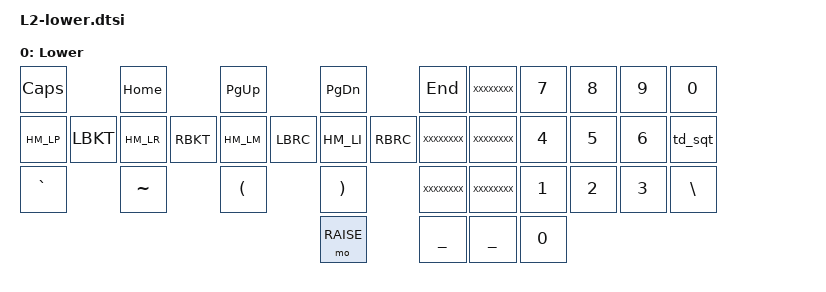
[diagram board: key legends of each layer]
/**
 *
 */

/ {
  keymap {
    compatible = "zmk,keymap";

	lower_layer {
		label = "Lower";
   		bindings = <
//					╭───────────────┬───────────────┬───────────────┬───────────────┬───────────────╮   ╭───────────────┬───────────────┬───────────────┬───────────────┬───────────────╮
//  0               	1               2               3               4               5                   6               7               8               9               10
			 			&kp CAPS		&kp HOME    	&kp PG_UP		&kp PG_DN		&kp END				XXXXXXXX		&kp N7			&kp N8       	&kp N9        	&kp N0
				//	├───────────────┼───────────────┼───────────────┼───────────────┼───────────────┤   ├───────────────├───────────────┼───────────────┼───────────────┼───────────────┤
//  12					13              14              15              16              17                  18              19              20              21              22
						HM_LP LBKT		HM_LR RBKT    	HM_LM LBRC 		HM_LI RBRC		XXXXXXXX			XXXXXXXX		&kp N4			&kp N5       	&kp N6			&td_sqt
//				//	├───────────────┼───────────────┼───────────────┼───────────────┼───────────────┤   ├───────────────├───────────────┼───────────────┼───────────────┼───────────────┤
//  24					25              26              27              28              29                  30              31              32              33              34
						&kp GRAVE		&kp TILDE    	&kp LPAR		&kp RPAR		XXXXXXXX			XXXXXXXX		&kp N1			&kp N2       	&kp N3			&kp BSLH
				//	╰───────────────┴───────────────┼───────────────┼───────────────┼───────────────┤   ├───────────────├───────────────┼───────────────┼───────────────┴───────────────╯
//	36              													37              38                  39              40
			       														&mo RAISE		________			________		&kp N0
//                                                                  ╰───────────────┴───────────────╯   ╰───────────────┴───────────────╯

			>;


		};
	};
};
